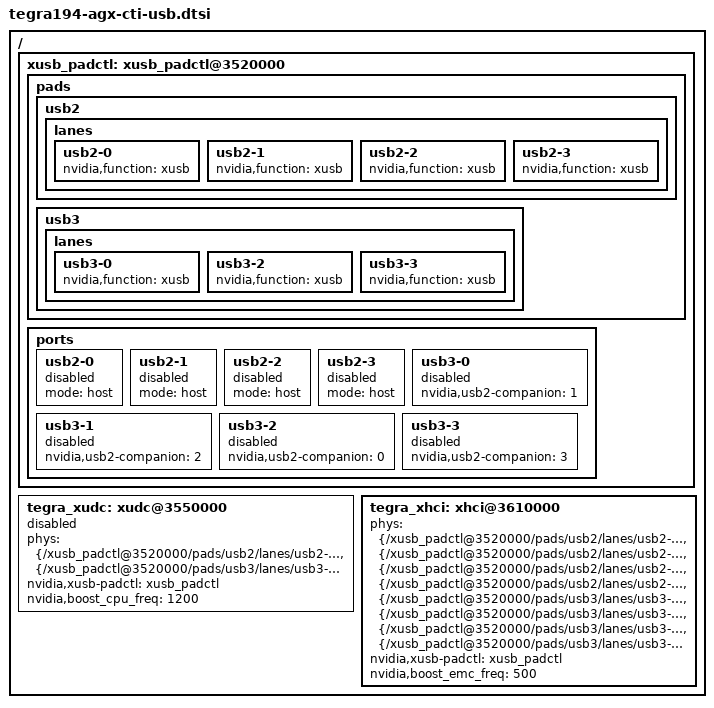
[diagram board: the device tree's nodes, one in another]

/ {
    xusb_padctl: xusb_padctl@3520000 {
        status = "okay";

        pads {
            usb2 {
                lanes {
                    usb2-0 {
                        nvidia,function = "xusb";
                        status = "okay";
                    };
                    usb2-1 {
                        nvidia,function = "xusb";
                        status = "okay";
                    };
                    usb2-2 {
                        nvidia,function = "xusb";
                        status = "okay";
                    };
                    usb2-3 {
                        nvidia,function = "xusb";
                        status = "okay";
                    };
                };
            };
            usb3 {
                lanes {
                    usb3-0 {
                        nvidia,function = "xusb";
                        status = "okay";
                    };
                    usb3-2 {
                        nvidia,function = "xusb";
                        status = "okay";
                    };
                    usb3-3 {
                        nvidia,function = "xusb";
                        status = "okay";
                    };
                };
            };
        };

        ports {
       /*     usb2-0 {
                mode = "otg";
                usb-role-switch;
                status = "okay";
#if TEGRA_XUSB_DT_VERSION >= DT_VERSION_3
                port {
                    usb_role_switch0: endpoint {
                        remote-endpoint = <&ucsi_ccg_p0>;
                    };
                };
#endif
            };
*/

            usb2-0 {
                mode = "host";
                status = "disabled";
            };
            usb2-1 {
                mode = "host";
                status = "disabled";
            };
            usb2-2 {
                mode = "host";
                status = "disabled";
            };
            usb2-3 {
                mode = "host";
                status = "disabled";
            };
            usb3-0 {
                nvidia,usb2-companion = <1>;
                status = "disabled";
            };
            usb3-1 {
                nvidia,usb2-companion = <2>;
                status = "disabled";
            };
            usb3-2 {
                nvidia,usb2-companion = <0>;
                status = "disabled";
            };
            usb3-3 {
                nvidia,usb2-companion = <3>;
                status = "disabled";
            };
        };
    };



    tegra_xudc: xudc@3550000 {
        status = "disabled";
        phys = <&{/xusb_padctl@3520000/pads/usb2/lanes/usb2-0}>,
               <&{/xusb_padctl@3520000/pads/usb3/lanes/usb3-2}>;

        phy-names = "usb2-0", "usb3-2";
        nvidia,xusb-padctl = <&xusb_padctl>;
        nvidia,boost_cpu_freq = <1200>;

    };

    tegra_xhci: xhci@3610000 {
        status = "okay";
        phys = <&{/xusb_padctl@3520000/pads/usb2/lanes/usb2-0}>,
            <&{/xusb_padctl@3520000/pads/usb2/lanes/usb2-1}>,
            <&{/xusb_padctl@3520000/pads/usb2/lanes/usb2-3}>,
            <&{/xusb_padctl@3520000/pads/usb2/lanes/usb2-2}>,
            <&{/xusb_padctl@3520000/pads/usb3/lanes/usb3-0}>,
            <&{/xusb_padctl@3520000/pads/usb3/lanes/usb3-1}>,
            <&{/xusb_padctl@3520000/pads/usb3/lanes/usb3-2}>,
            <&{/xusb_padctl@3520000/pads/usb3/lanes/usb3-3}>;
        phy-names = "usb2-0", "usb2-1", "usb2-3", "usb2-2",
                    "usb3-0", "usb3-1", "usb3-2", "usb3-3";
        nvidia,xusb-padctl = <&xusb_padctl>;
        nvidia,boost_emc_freq = <500>;
    };
};
